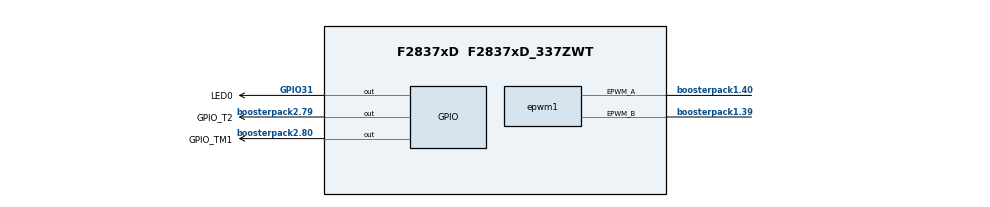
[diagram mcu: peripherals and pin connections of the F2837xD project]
/**
 * @cliArgs --board "/boards/LAUNCHXL_F28379D" --device "F2837xD" --part "F2837xD_337ZWT" --package "F2837xD_337ZWT" --context "CPU1" --product "C2000WARE@5.04.00.00"
 * @versions {"tool":"1.21.0+3721"}
 */

/**
 * Import the modules used in this configuration.
 */
const adc         = scripting.addModule("/driverlib/adc.js", {}, false);
const adc1        = adc.addInstance();
const led         = scripting.addModule("/driverlib/board_components/led", {}, false);
const led1        = led.addInstance();
const led2        = led.addInstance();
const cputimer    = scripting.addModule("/driverlib/cputimer.js", {}, false);
const cputimer1   = cputimer.addInstance();
const epwm        = scripting.addModule("/driverlib/epwm.js", {}, false);
const epwm1       = epwm.addInstance();
const gpio        = scripting.addModule("/driverlib/gpio.js", {}, false);
const gpio1       = gpio.addInstance();
const gpio2       = gpio.addInstance();
const FPUfastRTS  = scripting.addModule("/libraries/math/FPUfastRTS/FPUfastRTS.js", {}, false);
const FPUfastRTS1 = FPUfastRTS.addInstance();
const IQmath      = scripting.addModule("/libraries/math/IQmath/IQmath.js", {}, false);
const IQmath1     = IQmath.addInstance();

/**
 * Write custom configuration values to the imported modules.
 */
adc1.adcClockPrescaler       = "ADC_CLK_DIV_8_5";
adc1.enabledSOCs             = ["ADC_SOC_NUMBER0"];
adc1.$name                   = "myADC0";
adc1.soc0Trigger             = "ADC_TRIGGER_EPWM1_SOCA";
adc1.soc0SampleWindow        = 20;
adc1.interruptPulseMode      = "ADC_PULSE_END_OF_CONV";
adc1.enabledInts             = ["ADC_INT_NUMBER1"];
adc1.enableInterrupt1        = true;
adc1.registerInterrupts      = ["1"];
adc1.adcInt1.enableInterrupt = true;

led1.$hardware              = system.deviceData.board.components.LED4;
led1.$name                  = "LED0";
led1.gpio.writeInitialValue = true;
led1.gpio.gpioPin.$assign   = "GPIO31";

led2.$name                  = "LED1";
led2.$hardware              = system.deviceData.board.components.LED5;
led2.gpio.writeInitialValue = true;

cputimer1.$name                    = "I2T_TIMER_0";
cputimer1.timerPrescaler           = 200;
cputimer1.timerPeriod              = 1000;
cputimer1.registerInterrupts       = true;
cputimer1.enableInterrupt          = true;
cputimer1.timerInt.enableInterrupt = true;

epwm1.$name                    = "myEPWM0";
epwm1.epwmTimebase_hsClockDiv  = "EPWM_HSCLOCK_DIVIDER_1";
epwm1.epwmTimebase_period      = 3999;
epwm1.epwmTimebase_counterMode = "EPWM_COUNTER_MODE_UP";
epwm1.epwm.$assign             = "EPWM1";
epwm1.epwm.epwm_aPin.$assign   = "boosterpack1.40";
epwm1.epwm.epwm_bPin.$assign   = "boosterpack1.39";
scripting.suppress("Connected to hardware,@@@.+?@@@ is connected to EPWM1 BP on the LaunchPad F28379D\\. Consider selecting it in \'use hardware\' above\\. @@@.+?@@@", epwm1.epwm, "epwm_aPin");
scripting.suppress("Connected to hardware,@@@.+?@@@ is connected to EPWM1 BP on the LaunchPad F28379D\\. Consider selecting it in \'use hardware\' above\\. @@@.+?@@@", epwm1.epwm, "epwm_bPin");

gpio1.direction         = "GPIO_DIR_MODE_OUT";
gpio1.writeInitialValue = true;
gpio1.$name             = "GPIO_TM1";
gpio1.gpioPin.$assign   = "boosterpack2.80";
scripting.suppress("Connected to hardware,@@@.+?@@@ is connected to EPWM4 BP on the LaunchPad F28379D\\. Consider selecting it in \'use hardware\' above\\. @@@.+?@@@", gpio1, "gpioPin");

gpio2.$name             = "GPIO_T2";
gpio2.direction         = "GPIO_DIR_MODE_OUT";
gpio2.writeInitialValue = true;
gpio2.gpioPin.$assign   = "boosterpack2.79";
scripting.suppress("Connected to hardware,@@@.+?@@@ is connected to EPWM4 BP on the LaunchPad F28379D\\. Consider selecting it in \'use hardware\' above\\. @@@.+?@@@", gpio2, "gpioPin");

FPUfastRTS1.$name = "myFFR0";

IQmath1.$name = "myIQmath0";

/**
 * Pinmux solution for unlocked pins/peripherals. This ensures that minor changes to the automatic solver in a future
 * version of the tool will not impact the pinmux you originally saw.  These lines can be completely deleted in order to
 * re-solve from scratch.
 */
led2.gpio.gpioPin.$suggestSolution = "GPIO34";
